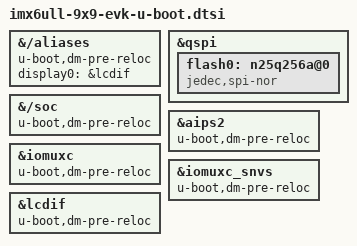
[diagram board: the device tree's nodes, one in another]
// SPDX-License-Identifier: GPL-2.0+
/*
 * Copyright 2018 NXP
 */

&{/aliases} {
	u-boot,dm-pre-reloc;
	display0 = &lcdif;
};

&qspi {
	flash0: n25q256a@0 {
		compatible = "jedec,spi-nor";
	};
};

&{/soc} {
	u-boot,dm-pre-reloc;
};

&aips2 {
	u-boot,dm-pre-reloc;
};

&iomuxc {
	u-boot,dm-pre-reloc;
};

&iomuxc_snvs {
	u-boot,dm-pre-reloc;
};

&lcdif {
	u-boot,dm-pre-reloc;
};
